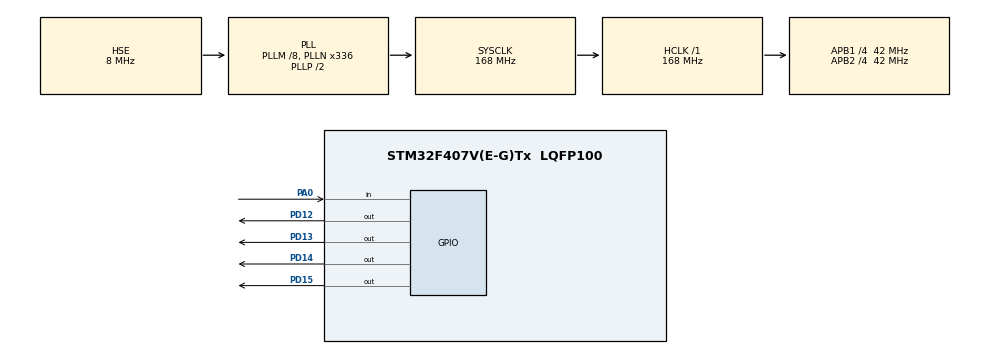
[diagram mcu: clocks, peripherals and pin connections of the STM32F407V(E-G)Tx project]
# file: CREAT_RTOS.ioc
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FREERTOS.Tasks01=LED_BLINK,0,128,LED_BLINKFunction,Default,NULL,Dynamic,NULL,NULL;LED_BUTTON,1,128,LED_BUTTONFunction,Default,NULL,Dynamic,NULL,NULL
Mcu.Family=STM32F4
Mcu.Name=STM32F407V(E-G)Tx
Mcu.Package=LQFP100
NVIC.PriorityGroup=NVIC_PRIORITYGROUP_4
NVIC.TIM1_UP_TIM10_IRQn=true\:15\:0\:false\:false\:true\:false\:false\:true
NVIC.TimeBase=TIM1_UP_TIM10_IRQn
NVIC.TimeBaseIP=TIM1
PA0-WKUP.Signal=GPIO_Input
PA13.Mode=Serial_Wire
PA13.Signal=SYS_JTMS-SWDIO
PA14.Mode=Serial_Wire
PA14.Signal=SYS_JTCK-SWCLK
PD12.Signal=GPIO_Output
PD13.Signal=GPIO_Output
PD14.Signal=GPIO_Output
PD15.Signal=GPIO_Output
PH0-OSC_IN.Mode=HSE-External-Oscillator
PH0-OSC_IN.Signal=RCC_OSC_IN
PH1-OSC_OUT.Mode=HSE-External-Oscillator
PH1-OSC_OUT.Signal=RCC_OSC_OUT
ProjectManager.HeapSize=0x200
ProjectManager.StackSize=0x400
ProjectManager.TargetToolchain=MDK-ARM V5
RCC.48MHZClocksFreq_Value=84000000
RCC.AHBFreq_Value=168000000
RCC.APB1CLKDivider=RCC_HCLK_DIV4
RCC.APB1Freq_Value=42000000
RCC.APB1TimFreq_Value=84000000
RCC.APB2CLKDivider=RCC_HCLK_DIV4
RCC.APB2Freq_Value=42000000
RCC.APB2TimFreq_Value=84000000
RCC.CortexFreq_Value=168000000
RCC.HCLKFreq_Value=168000000
RCC.HSE_VALUE=8000000
RCC.HSI_VALUE=16000000
RCC.LSE_VALUE=32768
RCC.PLLM=8
RCC.PLLN=336
RCC.PLLSourceVirtual=RCC_PLLSOURCE_HSE
RCC.SYSCLKFreq_VALUE=168000000
RCC.SYSCLKSource=RCC_SYSCLKSOURCE_PLLCLK
RCC.VCOOutputFreq_Value=336000000
VP_FREERTOS_VS_CMSIS_V1.Mode=CMSIS_V1
VP_SYS_VS_tim1.Mode=TIM1
board=custom

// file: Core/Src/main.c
/* USER CODE BEGIN Header */
/**
  ******************************************************************************
  * @file           : main.c
  * @brief          : Main program body
  ******************************************************************************
  * @attention
  *
  * Copyright (c) 2021 STMicroelectronics.
  * All rights reserved.
  *
  * This software is licensed under terms that can be found in the LICENSE file
  * in the root directory of this software component.
  * If no LICENSE file comes with this software, it is provided AS-IS.
  *
  ******************************************************************************
  */
/* USER CODE END Header */
#include "main.h"
#include "cmsis_os.h"

osThreadId LED_BLINKHandle;
osThreadId LED_BUTTONHandle;

void SystemClock_Config(void);
static void MX_GPIO_Init(void);
void LED_BLINKFunction(void const * argument);
void LED_BUTTONFunction(void const * argument);

/* USER CODE BEGIN 0 */
uint8_t value = 0;
/* USER CODE END 0 */

int main(void)
{

  /* MCU Configuration--------------------------------------------------------*/

  /* Reset of all peripherals, Initializes the Flash interface and the Systick. */
  HAL_Init();

  /* Configure the system clock */
  SystemClock_Config();

  /* Initialize all configured peripherals */
  MX_GPIO_Init();

  /* Create the thread(s) */
  /* definition and creation of LED_BLINK */
  osThreadDef(LED_BLINK, LED_BLINKFunction, osPriorityNormal, 0, 128);
  LED_BLINKHandle = osThreadCreate(osThread(LED_BLINK), NULL);

  /* definition and creation of LED_BUTTON */
  osThreadDef(LED_BUTTON, LED_BUTTONFunction, osPriorityAboveNormal, 0, 128);
  LED_BUTTONHandle = osThreadCreate(osThread(LED_BUTTON), NULL);

  /* Start scheduler */
  osKernelStart();

  /* We should never get here as control is now taken by the scheduler */
  /* Infinite loop */
  while (1)
  {

  }
}

void SystemClock_Config(void)
{
  RCC_OscInitTypeDef RCC_OscInitStruct = {0};
  RCC_ClkInitTypeDef RCC_ClkInitStruct = {0};

  /** Configure the main internal regulator output voltage
  */
  __HAL_RCC_PWR_CLK_ENABLE();
  __HAL_PWR_VOLTAGESCALING_CONFIG(PWR_REGULATOR_VOLTAGE_SCALE1);
  /** Initializes the RCC Oscillators according to the specified parameters
  * in the RCC_OscInitTypeDef structure.
  */
  RCC_OscInitStruct.OscillatorType = RCC_OSCILLATORTYPE_HSE;
  RCC_OscInitStruct.HSEState = RCC_HSE_ON;
  RCC_OscInitStruct.PLL.PLLState = RCC_PLL_ON;
  RCC_OscInitStruct.PLL.PLLSource = RCC_PLLSOURCE_HSE;
  RCC_OscInitStruct.PLL.PLLM = 8;
  RCC_OscInitStruct.PLL.PLLN = 336;
  RCC_OscInitStruct.PLL.PLLP = RCC_PLLP_DIV2;
  RCC_OscInitStruct.PLL.PLLQ = 4;
  if (HAL_RCC_OscConfig(&RCC_OscInitStruct) != HAL_OK)
  {
    Error_Handler();
  }
  /** Initializes the CPU, AHB and APB buses clocks
  */
  RCC_ClkInitStruct.ClockType = RCC_CLOCKTYPE_HCLK|RCC_CLOCKTYPE_SYSCLK
                              |RCC_CLOCKTYPE_PCLK1|RCC_CLOCKTYPE_PCLK2;
  RCC_ClkInitStruct.SYSCLKSource = RCC_SYSCLKSOURCE_PLLCLK;
  RCC_ClkInitStruct.AHBCLKDivider = RCC_SYSCLK_DIV1;
  RCC_ClkInitStruct.APB1CLKDivider = RCC_HCLK_DIV4;
  RCC_ClkInitStruct.APB2CLKDivider = RCC_HCLK_DIV4;

  if (HAL_RCC_ClockConfig(&RCC_ClkInitStruct, FLASH_LATENCY_5) != HAL_OK)
  {
    Error_Handler();
  }
}

static void MX_GPIO_Init(void)
{
  GPIO_InitTypeDef GPIO_InitStruct = {0};

  /* GPIO Ports Clock Enable */
  __HAL_RCC_GPIOH_CLK_ENABLE();
  __HAL_RCC_GPIOA_CLK_ENABLE();
  __HAL_RCC_GPIOD_CLK_ENABLE();

  /*Configure GPIO pin Output Level */
  HAL_GPIO_WritePin(GPIOD, GPIO_PIN_12|GPIO_PIN_13|GPIO_PIN_14|GPIO_PIN_15, GPIO_PIN_RESET);

  /*Configure GPIO pin : PA0 */
  GPIO_InitStruct.Pin = GPIO_PIN_0;
  GPIO_InitStruct.Mode = GPIO_MODE_INPUT;
  GPIO_InitStruct.Pull = GPIO_NOPULL;
  HAL_GPIO_Init(GPIOA, &GPIO_InitStruct);

  /*Configure GPIO pins : PD12 PD13 PD14 PD15 */
  GPIO_InitStruct.Pin = GPIO_PIN_12|GPIO_PIN_13|GPIO_PIN_14|GPIO_PIN_15;
  GPIO_InitStruct.Mode = GPIO_MODE_OUTPUT_PP;
  GPIO_InitStruct.Pull = GPIO_NOPULL;
  GPIO_InitStruct.Speed = GPIO_SPEED_FREQ_LOW;
  HAL_GPIO_Init(GPIOD, &GPIO_InitStruct);

}

void LED_BLINKFunction(void const * argument)
{
  /* USER CODE BEGIN 5 */
  /* Infinite loop */
  for(;;)
  {
		HAL_GPIO_WritePin(GPIOD, GPIO_PIN_12, GPIO_PIN_SET);
		HAL_Delay(100);//1000 ms
		HAL_GPIO_WritePin(GPIOD, GPIO_PIN_12, GPIO_PIN_RESET);
		HAL_Delay(100);//delay 1000 ms
    osDelay(1);// sleep 1 ms
  }
  /* USER CODE END 5 */
}

void LED_BUTTONFunction(void const * argument)
{
  /* USER CODE BEGIN LED_BUTTONFunction */
  /* Infinite loop */
  for(;;)
  {
		if(HAL_GPIO_ReadPin(GPIOA, GPIO_PIN_0) == 1)
		{
			HAL_GPIO_WritePin(GPIOD, GPIO_PIN_15, GPIO_PIN_SET);
		}
		else
		{
			HAL_GPIO_WritePin(GPIOD, GPIO_PIN_15, GPIO_PIN_RESET);
		}

    osDelay(1);//sleep 1 ms
  }
  /* USER CODE END LED_BUTTONFunction */
}

void HAL_TIM_PeriodElapsedCallback(TIM_HandleTypeDef *htim)
{
  if (htim->Instance == TIM1) {
    HAL_IncTick();
  }
}

void Error_Handler(void)
{
  __disable_irq();
  while (1)
  {
  }
}
